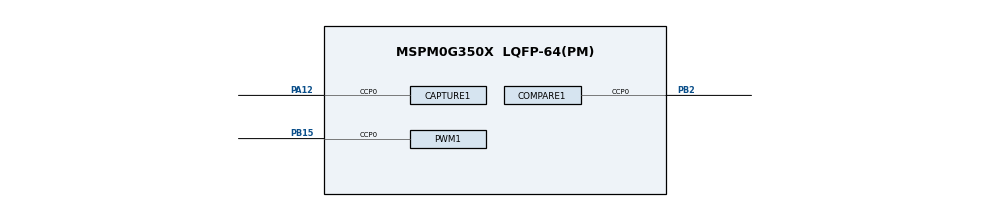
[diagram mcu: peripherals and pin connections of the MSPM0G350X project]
/**
 * @cliArgs --device "MSPM0G350X" --part "Default" --package "LQFP-64(PM)" --product "mspm0_sdk@2.10.00.04"
 * @versions {"tool":"1.26.2+4477"}
 */

/**
 * Import the modules used in this configuration.
 */
const CAPTURE  = scripting.addModule("/ti/driverlib/CAPTURE", {}, false);
const CAPTURE1 = CAPTURE.addInstance();
const COMPARE  = scripting.addModule("/ti/driverlib/COMPARE", {}, false);
const COMPARE1 = COMPARE.addInstance();
const PWM      = scripting.addModule("/ti/driverlib/PWM", {}, false);
const PWM1     = PWM.addInstance();
const TIMER    = scripting.addModule("/ti/driverlib/TIMER", {}, false);
const TIMER1   = TIMER.addInstance();

/**
 * Write custom configuration values to the imported modules.
 */
CAPTURE1.$name                      = "CAPTURE_0";
CAPTURE1.captMode                   = "COMBINED";
CAPTURE1.interrupts                 = ["CC1_DN","ZERO"];
CAPTURE1.timerPeriod                = "2 ms";
CAPTURE1.peripheral.$assign         = "TIMG0";
CAPTURE1.peripheral.ccp0Pin.$assign = "PA12";
CAPTURE1.ccp0PinConfig.$name        = "ti_driverlib_gpio_GPIOPinGeneric0";

const Board = scripting.addModule("/ti/driverlib/Board", {}, false);

COMPARE1.$name                      = "COMPARE_0";
COMPARE1.timerPeriod                = 65535;
COMPARE1.peripheral.$assign         = "TIMG6";
COMPARE1.peripheral.ccp0Pin.$assign = "PB2";
COMPARE1.ccp0PinConfig.$name        = "ti_driverlib_gpio_GPIOPinGeneric2";

PWM1.$name                      = "PWM_0";
PWM1.ccIndex                    = [0];
PWM1.clockPrescale              = 256;
PWM1.PWM_CHANNEL_0.$name        = "ti_driverlib_pwm_PWMTimerCC0";
PWM1.PWM_CHANNEL_0.dutyCycle    = 50;
PWM1.ccp0PinConfig.$name        = "ti_driverlib_gpio_GPIOPinGeneric1";
PWM1.peripheral.$assign         = "TIMG7";
PWM1.peripheral.ccp0Pin.$assign = "PB15";

const SYSCTL                 = scripting.addModule("/ti/driverlib/SYSCTL", {}, false);
SYSCTL.forceDefaultClkConfig = true;
SYSCTL.clockTreeEn           = true;

TIMER1.$name              = "TIMER_GATE";
TIMER1.timerClkPrescale   = 256;
TIMER1.timerMode          = "PERIODIC";
TIMER1.timerPeriod        = "100ms";
TIMER1.interrupts         = ["LOAD"];
TIMER1.timerStartTimer    = true;
TIMER1.peripheral.$assign = "TIMA0";

/**
 * Pinmux solution for unlocked pins/peripherals. This ensures that minor changes to the automatic solver in a future
 * version of the tool will not impact the pinmux you originally saw.  These lines can be completely deleted in order to
 * re-solve from scratch.
 */
Board.peripheral.$suggestSolution          = "DEBUGSS";
Board.peripheral.swclkPin.$suggestSolution = "PA20";
Board.peripheral.swdioPin.$suggestSolution = "PA19";
